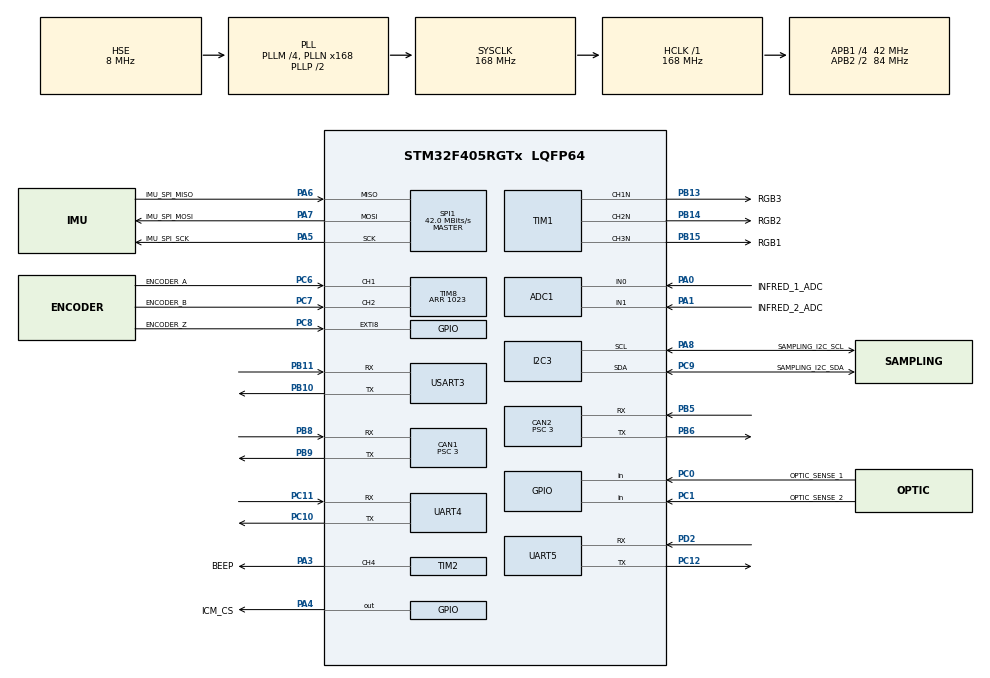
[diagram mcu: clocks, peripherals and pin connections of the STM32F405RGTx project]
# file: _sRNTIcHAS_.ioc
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ADC1.Channel-0\#ChannelRegularConversion=ADC_CHANNEL_0
ADC1.Channel-1\#ChannelRegularConversion=ADC_CHANNEL_1
ADC1.ClockPrescaler=ADC_CLOCK_SYNC_PCLK_DIV4
ADC1.ContinuousConvMode=ENABLE
ADC1.DMAContinuousRequests=ENABLE
ADC1.NbrOfConversion=2
ADC1.NbrOfConversionFlag=1
ADC1.Rank-0\#ChannelRegularConversion=1
ADC1.Rank-1\#ChannelRegularConversion=2
ADC1.SamplingTime-0\#ChannelRegularConversion=ADC_SAMPLETIME_112CYCLES
ADC1.SamplingTime-1\#ChannelRegularConversion=ADC_SAMPLETIME_112CYCLES
ADC1.ScanConvMode=ENABLE
ADC1.master=1
CAN1.ABOM=ENABLE
CAN1.BS1=CAN_BS1_9TQ
CAN1.BS2=CAN_BS2_4TQ
CAN1.CalculateTimeQuantum=71.42857142857143
CAN1.Prescaler=3
CAN2.ABOM=ENABLE
CAN2.BS1=CAN_BS1_9TQ
CAN2.BS2=CAN_BS2_4TQ
CAN2.CalculateTimeQuantum=71.42857142857143
CAN2.Prescaler=3
Dma.ADC1.0.Direction=DMA_PERIPH_TO_MEMORY
Dma.ADC1.0.FIFOMode=DMA_FIFOMODE_DISABLE
Dma.ADC1.0.Instance=DMA2_Stream0
Dma.ADC1.0.MemDataAlignment=DMA_MDATAALIGN_HALFWORD
Dma.ADC1.0.MemInc=DMA_MINC_ENABLE
Dma.ADC1.0.Mode=DMA_CIRCULAR
Dma.ADC1.0.PeriphDataAlignment=DMA_PDATAALIGN_HALFWORD
Dma.ADC1.0.PeriphInc=DMA_PINC_DISABLE
Dma.ADC1.0.Priority=DMA_PRIORITY_LOW
Dma.Request0=ADC1
Dma.Request1=UART4_RX
Dma.Request2=UART4_TX
Dma.Request3=UART5_RX
Dma.Request4=UART5_TX
Dma.Request5=USART3_RX
Dma.Request6=USART3_TX
Dma.UART4_RX.1.Direction=DMA_PERIPH_TO_MEMORY
Dma.UART4_RX.1.FIFOMode=DMA_FIFOMODE_DISABLE
Dma.UART4_RX.1.Instance=DMA1_Stream2
Dma.UART4_RX.1.MemDataAlignment=DMA_MDATAALIGN_BYTE
Dma.UART4_RX.1.MemInc=DMA_MINC_ENABLE
Dma.UART4_RX.1.Mode=DMA_NORMAL
Dma.UART4_RX.1.PeriphDataAlignment=DMA_PDATAALIGN_BYTE
Dma.UART4_RX.1.PeriphInc=DMA_PINC_DISABLE
Dma.UART4_RX.1.Priority=DMA_PRIORITY_LOW
Dma.UART4_TX.2.Direction=DMA_MEMORY_TO_PERIPH
Dma.UART4_TX.2.FIFOMode=DMA_FIFOMODE_DISABLE
Dma.UART4_TX.2.Instance=DMA1_Stream4
Dma.UART4_TX.2.MemDataAlignment=DMA_MDATAALIGN_BYTE
Dma.UART4_TX.2.MemInc=DMA_MINC_ENABLE
Dma.UART4_TX.2.Mode=DMA_NORMAL
Dma.UART4_TX.2.PeriphDataAlignment=DMA_PDATAALIGN_BYTE
Dma.UART4_TX.2.PeriphInc=DMA_PINC_DISABLE
Dma.UART4_TX.2.Priority=DMA_PRIORITY_LOW
Dma.UART5_RX.3.Direction=DMA_PERIPH_TO_MEMORY
Dma.UART5_RX.3.FIFOMode=DMA_FIFOMODE_DISABLE
Dma.UART5_RX.3.Instance=DMA1_Stream0
Dma.UART5_RX.3.MemDataAlignment=DMA_MDATAALIGN_BYTE
Dma.UART5_RX.3.MemInc=DMA_MINC_ENABLE
Dma.UART5_RX.3.Mode=DMA_NORMAL
Dma.UART5_RX.3.PeriphDataAlignment=DMA_PDATAALIGN_BYTE
Dma.UART5_RX.3.PeriphInc=DMA_PINC_DISABLE
Dma.UART5_RX.3.Priority=DMA_PRIORITY_LOW
Dma.UART5_TX.4.Direction=DMA_MEMORY_TO_PERIPH
Dma.UART5_TX.4.FIFOMode=DMA_FIFOMODE_DISABLE
Dma.UART5_TX.4.Instance=DMA1_Stream7
Dma.UART5_TX.4.MemDataAlignment=DMA_MDATAALIGN_BYTE
Dma.UART5_TX.4.MemInc=DMA_MINC_ENABLE
Dma.UART5_TX.4.Mode=DMA_NORMAL
Dma.UART5_TX.4.PeriphDataAlignment=DMA_PDATAALIGN_BYTE
Dma.UART5_TX.4.PeriphInc=DMA_PINC_DISABLE
Dma.UART5_TX.4.Priority=DMA_PRIORITY_LOW
Dma.USART3_RX.5.Direction=DMA_PERIPH_TO_MEMORY
Dma.USART3_RX.5.FIFOMode=DMA_FIFOMODE_DISABLE
Dma.USART3_RX.5.Instance=DMA1_Stream1
Dma.USART3_RX.5.MemDataAlignment=DMA_MDATAALIGN_BYTE
Dma.USART3_RX.5.MemInc=DMA_MINC_ENABLE
Dma.USART3_RX.5.Mode=DMA_NORMAL
Dma.USART3_RX.5.PeriphDataAlignment=DMA_PDATAALIGN_BYTE
Dma.USART3_RX.5.PeriphInc=DMA_PINC_DISABLE
Dma.USART3_RX.5.Priority=DMA_PRIORITY_LOW
Dma.USART3_TX.6.Direction=DMA_MEMORY_TO_PERIPH
Dma.USART3_TX.6.FIFOMode=DMA_FIFOMODE_DISABLE
Dma.USART3_TX.6.Instance=DMA1_Stream3
Dma.USART3_TX.6.MemDataAlignment=DMA_MDATAALIGN_BYTE
Dma.USART3_TX.6.MemInc=DMA_MINC_ENABLE
Dma.USART3_TX.6.Mode=DMA_NORMAL
Dma.USART3_TX.6.PeriphDataAlignment=DMA_PDATAALIGN_BYTE
Dma.USART3_TX.6.PeriphInc=DMA_PINC_DISABLE
Dma.USART3_TX.6.Priority=DMA_PRIORITY_LOW
FREERTOS.INCLUDE_vTaskDelayUntil=1
FREERTOS.MEMORY_ALLOCATION=0
FREERTOS.Tasks01=defaultTask,0,128,StartDefaultTask,Default,NULL,Dynamic,NULL,NULL
Mcu.Family=STM32F4
Mcu.Name=STM32F405RGTx
Mcu.Package=LQFP64
NVIC.CAN1_RX0_IRQn=true\:5\:0\:false\:false\:true\:true\:true\:true
NVIC.CAN2_RX0_IRQn=true\:5\:0\:false\:false\:true\:true\:true\:true
NVIC.DMA1_Stream0_IRQn=true\:5\:0\:false\:false\:true\:true\:false\:true
NVIC.DMA1_Stream1_IRQn=true\:5\:0\:false\:false\:true\:true\:false\:true
NVIC.DMA1_Stream2_IRQn=true\:5\:0\:false\:false\:true\:true\:false\:true
NVIC.DMA1_Stream3_IRQn=true\:5\:0\:false\:false\:true\:true\:false\:true
NVIC.DMA1_Stream4_IRQn=true\:5\:0\:false\:false\:true\:true\:false\:true
NVIC.DMA1_Stream7_IRQn=true\:5\:0\:false\:false\:true\:true\:false\:true
NVIC.DMA2_Stream0_IRQn=true\:5\:0\:false\:false\:true\:true\:false\:true
NVIC.PriorityGroup=NVIC_PRIORITYGROUP_4
NVIC.TIM7_IRQn=true\:0\:0\:false\:false\:true\:false\:false\:true
NVIC.TIM8_UP_TIM13_IRQn=true\:5\:0\:false\:false\:true\:true\:true\:true
NVIC.TimeBase=TIM7_IRQn
NVIC.TimeBaseIP=TIM7
NVIC.UART4_IRQn=true\:5\:0\:false\:false\:true\:true\:true\:true
NVIC.UART5_IRQn=true\:5\:0\:false\:false\:true\:true\:true\:true
NVIC.USART3_IRQn=true\:5\:0\:false\:false\:true\:true\:true\:true
PA0-WKUP.GPIO_Label=INFRED_1_ADC
PA0-WKUP.Signal=ADCx_IN0
PA1.GPIO_Label=INFRED_2_ADC
PA1.Signal=ADCx_IN1
PA13.Mode=Serial_Wire
PA13.Signal=SYS_JTMS-SWDIO
PA14.Mode=Serial_Wire
PA14.Signal=SYS_JTCK-SWCLK
PA3.GPIO_Label=BEEP
PA3.Signal=S_TIM2_CH4
PA4.GPIO_Label=ICM_CS
PA4.Signal=GPIO_Output
PA5.GPIO_Label=IMU_SPI_SCK
PA5.Mode=Full_Duplex_Master
PA5.Signal=SPI1_SCK
PA6.GPIO_Label=IMU_SPI_MISO
PA6.Mode=Full_Duplex_Master
PA6.Signal=SPI1_MISO
PA7.GPIO_Label=IMU_SPI_MOSI
PA7.Mode=Full_Duplex_Master
PA7.Signal=SPI1_MOSI
PA8.GPIO_Label=SAMPLING_I2C_SCL
PA8.Mode=I2C
PA8.Signal=I2C3_SCL
PB10.Mode=Asynchronous
PB10.Signal=USART3_TX
PB11.Mode=Asynchronous
PB11.Signal=USART3_RX
PB13.GPIO_Label=RGB3
PB13.Mode=PWM Generation1 CH1N
PB13.Signal=TIM1_CH1N
PB14.GPIO_Label=RGB2
PB14.Mode=PWM Generation2 CH2N
PB14.Signal=TIM1_CH2N
PB15.GPIO_Label=RGB1
PB15.Mode=Output Compare3 CH3N
PB15.Signal=TIM1_CH3N
PB5.Mode=Slave
PB5.Signal=CAN2_RX
PB6.Mode=Slave
PB6.Signal=CAN2_TX
PB8.Mode=Master
PB8.Signal=CAN1_RX
PB9.Mode=Master
PB9.Signal=CAN1_TX
PC0.GPIO_Label=OPTIC_SENSE_1
PC0.Signal=GPIO_Input
PC1.GPIO_Label=OPTIC_SENSE_2
PC1.Signal=GPIO_Input
PC10.Mode=Asynchronous
PC10.Signal=UART4_TX
PC11.Mode=Asynchronous
PC11.Signal=UART4_RX
PC12.Mode=Asynchronous
PC12.Signal=UART5_TX
PC6.GPIO_Label=ENCODER_A
PC6.Signal=S_TIM8_CH1
PC7.GPIO_Label=ENCODER_B
PC7.Signal=S_TIM8_CH2
PC8.GPIO_Label=ENCODER_Z
PC8.Signal=GPXTI8
PC9.GPIO_Label=SAMPLING_I2C_SDA
PC9.Mode=I2C
PC9.Signal=I2C3_SDA
PD2.Mode=Asynchronous
PD2.Signal=UART5_RX
PH0-OSC_IN.Mode=HSE-External-Oscillator
PH0-OSC_IN.Signal=RCC_OSC_IN
PH1-OSC_OUT.Mode=HSE-External-Oscillator
PH1-OSC_OUT.Signal=RCC_OSC_OUT
ProjectManager.HeapSize=0x200
ProjectManager.StackSize=0x400
ProjectManager.TargetToolchain=MDK-ARM V5
RCC.48MHZClocksFreq_Value=84000000
RCC.AHBFreq_Value=168000000
RCC.APB1CLKDivider=RCC_HCLK_DIV4
RCC.APB1Freq_Value=42000000
RCC.APB1TimFreq_Value=84000000
RCC.APB2CLKDivider=RCC_HCLK_DIV2
RCC.APB2Freq_Value=84000000
RCC.APB2TimFreq_Value=168000000
RCC.CortexFreq_Value=168000000
RCC.HCLKFreq_Value=168000000
RCC.HSE_VALUE=8000000
RCC.HSI_VALUE=16000000
RCC.LSE_VALUE=32768
RCC.PLLM=4
RCC.PLLN=168
RCC.PLLSourceVirtual=RCC_PLLSOURCE_HSE
RCC.SYSCLKFreq_VALUE=168000000
RCC.SYSCLKSource=RCC_SYSCLKSOURCE_PLLCLK
RCC.VCOOutputFreq_Value=336000000
SH.ADCx_IN0.0=ADC1_IN0,IN0
SH.ADCx_IN1.0=ADC1_IN1,IN1
SH.S_TIM2_CH4.0=TIM2_CH4,PWM Generation4 CH4
SH.S_TIM8_CH1.0=TIM8_CH1,Encoder_Interface
SH.S_TIM8_CH2.0=TIM8_CH2,Encoder_Interface
SPI1.CalculateBaudRate=42.0 MBits/s
SPI1.Direction=SPI_DIRECTION_2LINES
SPI1.Mode=SPI_MODE_MASTER
SPI1.VirtualType=VM_MASTER
TIM1.Channel-Output\ Compare3\ CH3N=TIM_CHANNEL_3
TIM1.Channel-PWM\ Generation1\ CH1N=TIM_CHANNEL_1
TIM1.Channel-PWM\ Generation2\ CH2N=TIM_CHANNEL_2
TIM2.Channel-PWM\ Generation4\ CH4=TIM_CHANNEL_4
TIM8.AutoReloadPreload=TIM_AUTORELOAD_PRELOAD_ENABLE
TIM8.EncoderMode=TIM_ENCODERMODE_TI12
TIM8.Period=1023
UART4.VirtualMode=Asynchronous
UART5.VirtualMode=Asynchronous
USART3.VirtualMode=VM_ASYNC
VP_FREERTOS_VS_CMSIS_V1.Mode=CMSIS_V1
VP_SYS_VS_tim7.Mode=TIM7
board=custom

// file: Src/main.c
/* USER CODE BEGIN Header */
/**
  ******************************************************************************
  * @file           : main.c
  * @brief          : Main program body
  ******************************************************************************
  * @attention
  *
  * <h2><center>&copy; Copyright (c) 2019 STMicroelectronics.
  * All rights reserved.</center></h2>
  *
  * This software component is licensed by ST under Ultimate Liberty license
  * SLA0044, the "License"; You may not use this file except in compliance with
  * the License. You may obtain a copy of the License at:
  *                             www.st.com/SLA0044
  *
  ******************************************************************************
  */
/* USER CODE END Header */

#include "main.h"
#include "cmsis_os.h"
#include "adc.h"
#include "can.h"
#include "dma.h"
#include "i2c.h"
#include "spi.h"
#include "tim.h"
#include "usart.h"
#include "gpio.h"

/* USER CODE BEGIN Includes */
#include "bsp_stddef.h"
/* USER CODE END Includes */

void SystemClock_Config(void);
void MX_FREERTOS_Init(void);

int main(void)
{

  /* MCU Configuration--------------------------------------------------------*/

  /* Reset of all peripherals, Initializes the Flash interface and the Systick. */
  HAL_Init();

  /* Configure the system clock */
  SystemClock_Config();

  /* Initialize all configured peripherals */
  MX_GPIO_Init();
  MX_DMA_Init();
  MX_ADC1_Init();
  MX_CAN1_Init();
  MX_CAN2_Init();
  MX_SPI1_Init();
  MX_TIM1_Init();
  MX_TIM8_Init();
  MX_UART4_Init();
  MX_UART5_Init();
  MX_USART3_UART_Init();
  MX_I2C3_Init();
  MX_TIM2_Init();

  /* Call init function for freertos objects (in freertos.c) */
  MX_FREERTOS_Init();

  /* Start scheduler */
  osKernelStart();

  /* We should never get here as control is now taken by the scheduler */

  /* Infinite loop */
  while (1)
  {

  }
}

void SystemClock_Config(void)
{
  RCC_OscInitTypeDef RCC_OscInitStruct = {0};
  RCC_ClkInitTypeDef RCC_ClkInitStruct = {0};

  /** Configure the main internal regulator output voltage
  */
  __HAL_RCC_PWR_CLK_ENABLE();
  __HAL_PWR_VOLTAGESCALING_CONFIG(PWR_REGULATOR_VOLTAGE_SCALE1);
  /** Initializes the CPU, AHB and APB busses clocks
  */
  RCC_OscInitStruct.OscillatorType = RCC_OSCILLATORTYPE_HSE;
  RCC_OscInitStruct.HSEState = RCC_HSE_ON;
  RCC_OscInitStruct.PLL.PLLState = RCC_PLL_ON;
  RCC_OscInitStruct.PLL.PLLSource = RCC_PLLSOURCE_HSE;
  RCC_OscInitStruct.PLL.PLLM = 4;
  RCC_OscInitStruct.PLL.PLLN = 168;
  RCC_OscInitStruct.PLL.PLLP = RCC_PLLP_DIV2;
  RCC_OscInitStruct.PLL.PLLQ = 4;
  if (HAL_RCC_OscConfig(&RCC_OscInitStruct) != HAL_OK)
  {
    Error_Handler();
  }
  /** Initializes the CPU, AHB and APB busses clocks
  */
  RCC_ClkInitStruct.ClockType = RCC_CLOCKTYPE_HCLK|RCC_CLOCKTYPE_SYSCLK
                              |RCC_CLOCKTYPE_PCLK1|RCC_CLOCKTYPE_PCLK2;
  RCC_ClkInitStruct.SYSCLKSource = RCC_SYSCLKSOURCE_PLLCLK;
  RCC_ClkInitStruct.AHBCLKDivider = RCC_SYSCLK_DIV1;
  RCC_ClkInitStruct.APB1CLKDivider = RCC_HCLK_DIV4;
  RCC_ClkInitStruct.APB2CLKDivider = RCC_HCLK_DIV2;

  if (HAL_RCC_ClockConfig(&RCC_ClkInitStruct, FLASH_LATENCY_5) != HAL_OK)
  {
    Error_Handler();
  }
}

void HAL_TIM_PeriodElapsedCallback(TIM_HandleTypeDef *htim)
{
  if (htim->Instance == TIM7) {
    HAL_IncTick();
  }
}

void Error_Handler(void)
{
}

#ifdef  USE_FULL_ASSERT
/**
  * @brief  Reports the name of the source file and the source line number
  *         where the assert_param error has occurred.
  * @param  file: pointer to the source file name
  * @param  line: assert_param error line source number
  * @retval None
  */
void assert_failed(uint8_t *file, uint32_t line)
{
  /* USER CODE BEGIN 6 */
  /* User can add his own implementation to report the file name and line number,
     tex: printf("Wrong parameters value: file %s on line %d\r\n", file, line) */
     printf("Wrong parameters value: file %s on line %d\r\n", file, line)
  /* USER CODE END 6 */
}
#endif /* USE_FULL_ASSERT */

/************************ (C) COPYRIGHT STMicroelectronics *****END OF FILE****/

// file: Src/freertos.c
/* USER CODE BEGIN Header */
/**
  ******************************************************************************
  * File Name          : freertos.c
  * Description        : Code for freertos applications
  ******************************************************************************
  * @attention
  *
  * <h2><center>&copy; Copyright (c) 2019 STMicroelectronics.
  * All rights reserved.</center></h2>
  *
  * This software component is licensed by ST under Ultimate Liberty license
  * SLA0044, the "License"; You may not use this file except in compliance with
  * the License. You may obtain a copy of the License at:
  *                             www.st.com/SLA0044
  *
  ******************************************************************************
  */
/* USER CODE END Header */

#include "FreeRTOS.h"
#include "task.h"
#include "main.h"
#include "cmsis_os.h"

/* USER CODE BEGIN Includes */
#include "task_sentCha.hpp"
/* USER CODE END Includes */

osThreadId defaultTaskHandle;

void StartDefaultTask(void const * argument);

void MX_FREERTOS_Init(void); /* (MISRA C 2004 rule 8.1) */

void MX_FREERTOS_Init(void) {

  /* Create the thread(s) */
  /* definition and creation of defaultTask */
  osThreadDef(defaultTask, StartDefaultTask, osPriorityNormal, 0, 128);
  defaultTaskHandle = osThreadCreate(osThread(defaultTask), NULL);

  /* USER CODE BEGIN RTOS_THREADS */
  /* add threads, ... */
  TaskStarter();
  /* USER CODE END RTOS_THREADS */

}

void StartDefaultTask(void const * argument)
{

  for(;;)
  {
    osDelay(1);
  }
}

/************************ (C) COPYRIGHT STMicroelectronics *****END OF FILE****/
